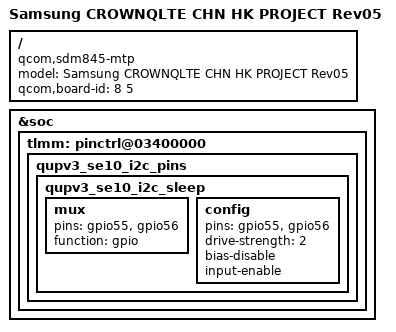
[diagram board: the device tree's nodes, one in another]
/* Copyright (c) 2016-2017, The Linux Foundation. All rights reserved.
 *
 * This program is free software; you can redistribute it and/or modify
 * it under the terms of the GNU General Public License version 2 and
 * only version 2 as published by the Free Software Foundation.
 *
 * This program is distributed in the hope that it will be useful,
 * but WITHOUT ANY WARRANTY; without even the implied warranty of
 * MERCHANTABILITY or FITNESS FOR A PARTICULAR PURPOSE.  See the
 * GNU General Public License for more details.
 */

/dts-v1/;

#include "../qcom/sdm845-v2.1.dtsi"
#include "../qcom/sdm845-mtp.dtsi"
#include "sdm845-sec-common.dtsi"
#include "sdm845-sec-crownqlte-pm-common.dtsi"
#include "sdm845-sec-crownqlte-pm-r02.dtsi"
#include "sdm845-sec-crownqlte-r05.dtsi"
#include "sdm845-sec-crownqlte-chn-pinctrl-r05.dtsi"
#include "battery-data-crownq-3000mAh.dtsi"
#include "sdm845-sec-crownqlte-display-r00.dtsi"
#include "sdm845-sec-crownqlte-displayport-r00.dtsi"
#include "sdm845-sec-crownqlte-fingerprint-sensor-r04.dtsi"
#include "sdm845-sec-crownqlte-chn-nfc-r03.dtsi"
#include "sdm845-sec-starqlte-mst-r00.dtsi"
#include "sdm845-camera-sensor-crownqlte-r00.dtsi"
#include "sdm845-starq-max77705.dtsi"

/ {
	model = "Samsung CROWNQLTE CHN HK PROJECT Rev05";
	compatible = "qcom,sdm845-mtp", "qcom,sdm845", "qcom,mtp";
	qcom,board-id = <8 5>;
};

&soc {
	tlmm: pinctrl@03400000 {
		qupv3_se10_i2c_pins: qupv3_se10_i2c_pins {
			/delete-node/ qupv3_se10_i2c_sleep;
			qupv3_se10_i2c_sleep: qupv3_se10_i2c_sleep {
				mux {
					pins = "gpio55", "gpio56";
					function = "gpio";
				};
				config {
					pins = "gpio55", "gpio56";
					drive-strength = <2>;
					bias-disable;
					input-enable;
				};
			};
		};
	};
};
